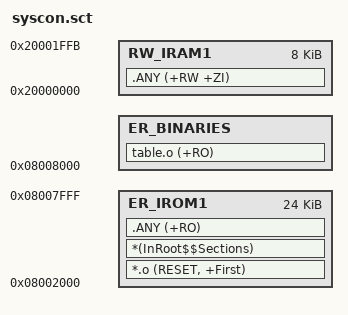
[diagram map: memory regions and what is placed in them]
LR_IROM1 0x08002000 0x0000E000  {    ; load region size_region
  ER_IROM1 0x08002000 0x00006000  {  ; load address = execution address
   *.o (RESET, +First)
   *(InRoot$$Sections)
   .ANY (+RO)
  }
  RW_IRAM1 0x20000000 0x00001FFC  {  ; RW data
   .ANY (+RW +ZI)
  }
  ER_BINARIES 0x08008000 ALIGN 0x8000 {
   	table.o (+RO)
  }
}
